AUTOSAR XML (schema 4-2-2)
package /ComponentTypes
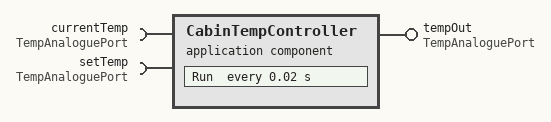
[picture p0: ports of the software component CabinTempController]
  application sw component type CabinTempController
    require port currentTemp: required-com-specs=[{data-element=tempIn, init-value=0}, {data-element=tempOut, init-value=0}], required-interface=TempAnaloguePort
    require port setTemp: required-com-specs=[{data-element=tempIn, init-value=0}, {data-element=tempOut, init-value=0}], required-interface=TempAnaloguePort
    provide port tempOut: provided-com-specs=[{data-element=tempIn, init-value=0}, {data-element=tempOut, init-value=0}], provided-interface=TempAnaloguePort
    behavior CabinTempController_InternalBehavior: data-type-mapping=tempMapSet
      4 x data received event, all with start-on-event=Run:
        DRT_Run_currentTemp_tempIn: data=currentTemp.tempIn
        DRT_Run_currentTemp_tempOut: data=currentTemp.tempOut
        DRT_Run_setTemp_tempIn: data=setTemp.tempIn
        DRT_Run_setTemp_tempOut: data=setTemp.tempOut
      timing event TMT_Run: start-on-event=Run, period=0.02
      runnable Run
        data-receive-point-by-arguments:
          4 x access:
            REC_currentTemp_tempIn: accessed-variable=currentTemp.tempIn
            REC_currentTemp_tempOut: accessed-variable=currentTemp.tempOut
            REC_setTemp_tempIn: accessed-variable=setTemp.tempIn
            REC_setTemp_tempOut: accessed-variable=setTemp.tempOut
        data-send-points:
          access SEND_tempOut_tempIn: accessed-variable=tempOut.tempIn
          access SEND_tempOut_tempOut: accessed-variable=tempOut.tempOut
  swc implementation CabinTempController_Implementation: behavior=CabinTempController_InternalBehavior
